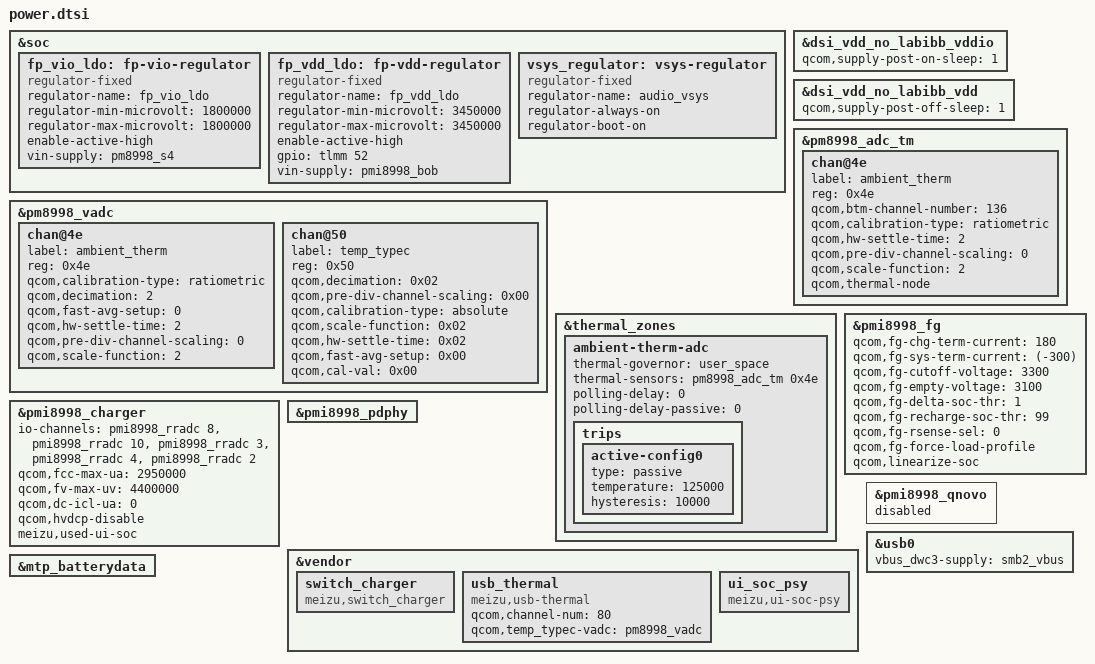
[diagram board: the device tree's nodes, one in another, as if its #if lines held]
/*
 * Copyright (c) 2024, MeizuCustoms enthusiasts
 *
 * This program is free software; you can redistribute it and/or modify
 * it under the terms of the GNU General Public License version 2 and
 * only version 2 as published by the Free Software Foundation.
 *
 * This program is distributed in the hope that it will be useful,
 * but WITHOUT ANY WARRANTY; without even the implied warranty of
 * MERCHANTABILITY or FITNESS FOR A PARTICULAR PURPOSE.  See the
 * GNU General Public License for more details.
 */

&soc {
	fp_vio_ldo: fp-vio-regulator {
		compatible = "regulator-fixed";
		regulator-name = "fp_vio_ldo";
		regulator-min-microvolt = <1800000>;
		regulator-max-microvolt = <1800000>;
		enable-active-high;
		vin-supply = <&pm8998_s4>;
	};

	fp_vdd_ldo: fp-vdd-regulator {
		compatible = "regulator-fixed";
		regulator-name = "fp_vdd_ldo";
		regulator-min-microvolt = <3450000>;
		regulator-max-microvolt = <3450000>;
		enable-active-high;

		gpio = <&tlmm 52 0x0>;
		vin-supply = <&pmi8998_bob>;
	};

	vsys_regulator: vsys-regulator {
		compatible = "regulator-fixed";
		regulator-name = "audio_vsys";
		regulator-always-on;
		regulator-boot-on;
	};
};

&dsi_vdd_no_labibb_vddio {
	qcom,supply-post-on-sleep = <1>;
};

&dsi_vdd_no_labibb_vdd {
	qcom,supply-post-off-sleep = <1>;
	/delete-property/ qcom,supply-post-on-sleep;
};

&pm8998_adc_tm {
	chan@4e {
		label = "ambient_therm";
		reg = <0x4e>;

		qcom,btm-channel-number = <136>;
		qcom,calibration-type = "ratiometric";
		qcom,hw-settle-time = <2>;
		qcom,pre-div-channel-scaling = <0>;
		qcom,scale-function = <2>;
		qcom,thermal-node;
	};
};

&pm8998_vadc {
	chan@4e {
		label = "ambient_therm";
		reg = <0x4e>;

		qcom,calibration-type = "ratiometric";
		qcom,decimation = <2>;
		qcom,fast-avg-setup = <0>;
		qcom,hw-settle-time = <2>;
		qcom,pre-div-channel-scaling = <0>;
		qcom,scale-function = <2>;
	};

    chan@50 {
        label = "temp_typec";
        reg = <0x50>;
        qcom,decimation = <0x02>;
        qcom,pre-div-channel-scaling = <0x00>;
        qcom,calibration-type = "absolute";
        qcom,scale-function = <0x02>;
        qcom,hw-settle-time = <0x02>;
        qcom,fast-avg-setup = <0x00>;
        qcom,cal-val = <0x00>;
    };
};

&thermal_zones {
	ambient-therm-adc {
		thermal-governor = "user_space";
		thermal-sensors = <&pm8998_adc_tm 0x4e>;
		polling-delay = <0>;
		polling-delay-passive = <0>;

		trips {
			active-config0 {
				type = "passive";
				temperature = <125000>;
				hysteresis = <10000>;
			};
		};
	};
};

&pmi8998_charger {
	io-channels = 
		<&pmi8998_rradc 8>,
		<&pmi8998_rradc 10>,
		<&pmi8998_rradc 3>,
		<&pmi8998_rradc 4>,
		<&pmi8998_rradc 2>;
	io-channel-names = 
		"charger_temp", 
		"charger_temp_max", 
		"usbin_i", 
		"usbin_v", 
		"skin_temp";
	
	qcom,fcc-max-ua = <2950000>;
	qcom,fv-max-uv = <4400000>;
	qcom,dc-icl-ua = <0>;

	qcom,hvdcp-disable;
	meizu,used-ui-soc;

    status = "ok";
};

&pmi8998_fg {
	qcom,fg-chg-term-current = <180>;
	qcom,fg-sys-term-current = <(-300)>;

	qcom,fg-cutoff-voltage = <3300>;
	qcom,fg-empty-voltage = <3100>;
	qcom,fg-delta-soc-thr = <1>;

	qcom,fg-recharge-soc-thr = <99>;
	qcom,fg-rsense-sel = <0>;

	qcom,fg-force-load-profile;
	qcom,linearize-soc;
};

&pmi8998_pdphy {
	status = "ok";
};

&vendor {
    switch_charger: switch_charger {
        compatible = "meizu,switch_charger";
    };

    usb_thermal: usb_thermal {
        compatible = "meizu,usb-thermal";
        qcom,channel-num = <80>;
        qcom,temp_typec-vadc = <&pm8998_vadc>;
    };

    ui_soc_psy: ui_soc_psy {
        compatible = "meizu,ui-soc-psy";
    };
};

&pmi8998_qnovo {
	status = "disabled";
};

&usb0 {
	vbus_dwc3-supply = <&smb2_vbus>;
};

&mtp_batterydata {
#ifdef MZ_M1892
    #include "battery-m1892-3600mah.dtsi"
#else
    #include "battery-3511331-meizu-m1882gy-3010mah-averaged-masterslave-jun4th2018.dtsi"
    #include "battery-3511331-meizu-m1882atl-3010mah-averaged-masterslave-jun4th2018.dtsi"
#endif

    /delete-node/ qcom,ascent_3450mah;
    /delete-node/ qcom,demo_6000mah;
    /delete-node/ qcom,itech_3000mah;
};
